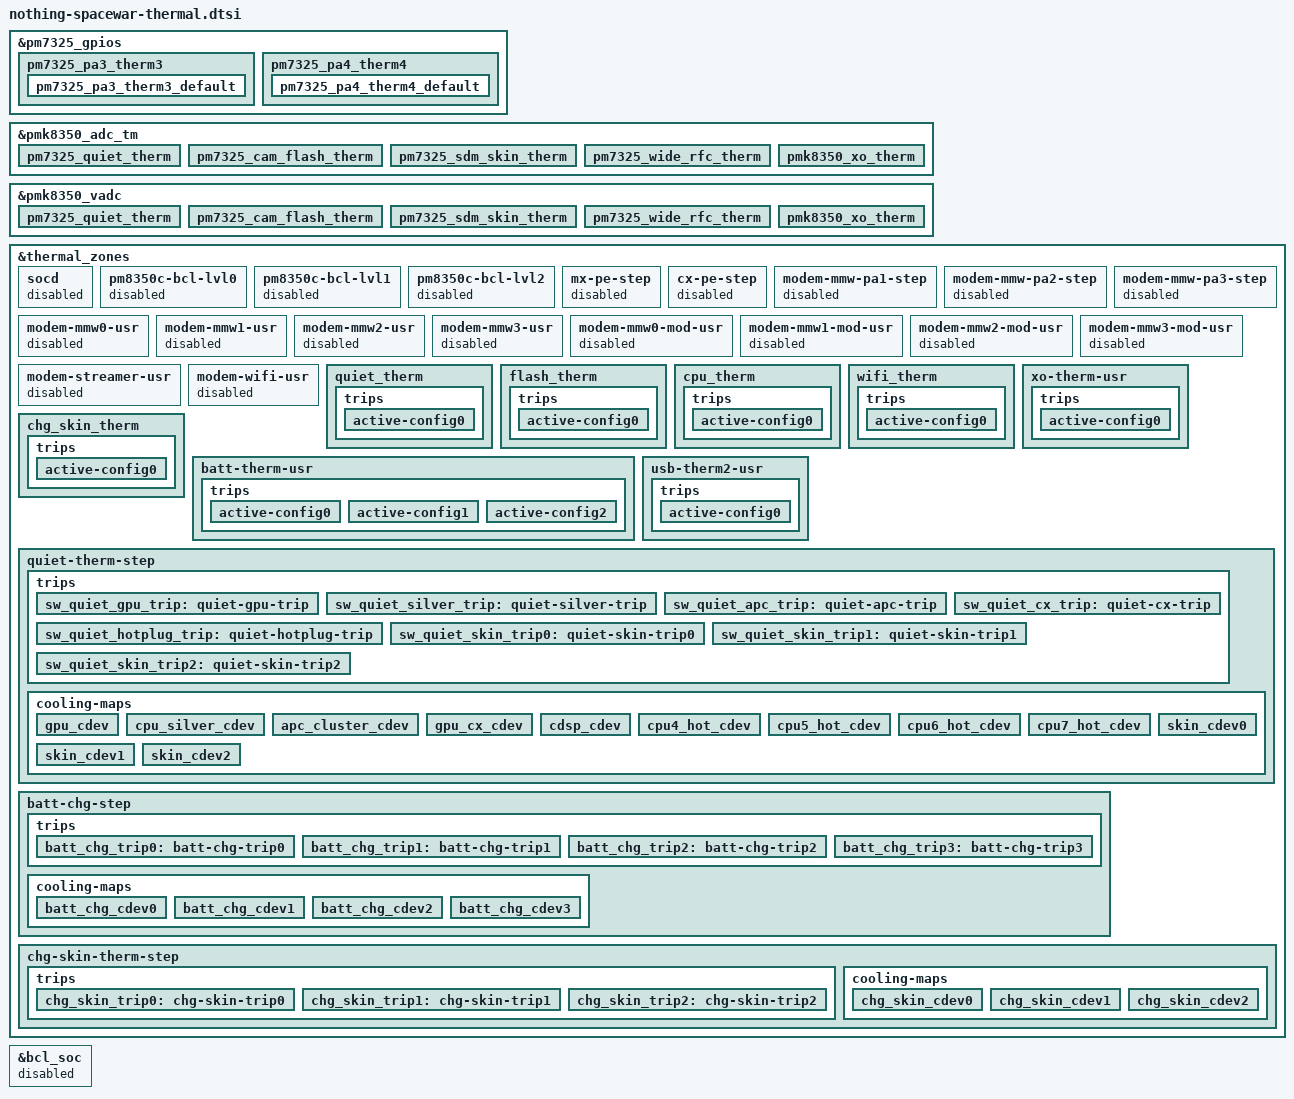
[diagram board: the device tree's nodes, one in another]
#include <dt-bindings/thermal/thermal_qti.h>
#include <dt-bindings/iio/qcom,spmi-adc7-pm7325.h>
#include <dt-bindings/iio/qcom,spmi-adc7-pm8350b.h>
#include <dt-bindings/iio/qcom,spmi-adc7-pmk8350.h>

&pm7325_gpios {
	pm7325_pa3_therm3 {
		pm7325_pa3_therm3_default: pm7325_pa3_therm3_default {
			pins = "gpio2";
			function = "normal";
			bias-high-impedance;
			status = "okay";
		};
	};

	pm7325_pa4_therm4 {
		pm7325_pa4_therm4_default: pm7325_pa4_therm4_default {
			pins = "gpio3";
			function = "normal";
			bias-high-impedance;
			status = "okay";
		};
	};
};

&pmk8350_adc_tm {
	pm7325_quiet_therm {
		reg = <PM7325_ADC7_AMUX_THM1_100K_PU>;
		qcom,ratiometric;
		qcom,hw-settle-time = <200>;
	};

	pm7325_cam_flash_therm {
		reg = <PM7325_ADC7_AMUX_THM2_100K_PU>;
		qcom,ratiometric;
		qcom,hw-settle-time = <200>;
	};

	pm7325_sdm_skin_therm {
		reg = <PM7325_ADC7_AMUX_THM3_100K_PU>;
		qcom,ratiometric;
		qcom,hw-settle-time = <200>;
	};

	pm7325_wide_rfc_therm {
		reg = <PM7325_ADC7_AMUX_THM4_100K_PU>;
		qcom,ratiometric;
		qcom,hw-settle-time = <200>;
	};

	pmk8350_xo_therm {
		reg = <PMK8350_ADC7_AMUX_THM1_100K_PU>;
		qcom,ratiometric;
		qcom,hw-settle-time = <200>;
	};
};

&pmk8350_vadc {
	pm7325_quiet_therm {
		label = "pm7325_quiet_therm";
		reg = <PM7325_ADC7_AMUX_THM1_100K_PU>;
		qcom,ratiometric;
		qcom,hw-settle-time = <200>;
		qcom,pre-scaling = <1 1>;
	};

	pm7325_cam_flash_therm {
		label = "pm7325_cam_flash_therm";
		reg = <PM7325_ADC7_AMUX_THM2_100K_PU>;
		qcom,ratiometric;
		qcom,hw-settle-time = <200>;
		qcom,pre-scaling = <1 1>;
	};

	pm7325_sdm_skin_therm {
		label = "pm7325_sdm_skin_therm";
		reg = <PM7325_ADC7_AMUX_THM3_100K_PU>;
		qcom,ratiometric;
		qcom,hw-settle-time = <200>;
		qcom,pre-scaling = <1 1>;
	};

	pm7325_wide_rfc_therm {
		label = "pm7325_wide_rfc_therm";
		reg = <PM7325_ADC7_AMUX_THM4_100K_PU>;
		qcom,ratiometric;
		qcom,hw-settle-time = <200>;
		qcom,pre-scaling = <1 1>;
	};

	pmk8350_xo_therm {
		label = "pmk8350_xo_therm";
		reg = <PMK8350_ADC7_AMUX_THM1_100K_PU>;
		qcom,ratiometric;
		qcom,hw-settle-time = <200>;
		qcom,pre-scaling = <1 1>;
	};
};

&thermal_zones {
	/delete-node/ pmr735a_tz;

	socd {
		status = "disabled";
		/delete-node/ cooling-maps;
	};

	pm8350c-bcl-lvl0 {
		status = "disabled";
	};

	pm8350c-bcl-lvl1 {
		status = "disabled";
	};

	pm8350c-bcl-lvl2 {
		status = "disabled";
	};

	mx-pe-step {
		status = "disabled";
	};

	cx-pe-step {
		status = "disabled";
	};

	modem-mmw-pa1-step {
		status = "disabled";
	};

	modem-mmw-pa2-step {
		status = "disabled";
	};

	modem-mmw-pa3-step {
		status = "disabled";
	};

	modem-mmw0-usr {
		status = "disabled";
	};

	modem-mmw1-usr {
		status = "disabled";
	};

	modem-mmw2-usr {
		status = "disabled";
	};

	modem-mmw3-usr {
		status = "disabled";
	};

	modem-mmw0-mod-usr {
		status = "disabled";
	};

	modem-mmw1-mod-usr {
		status = "disabled";
	};

	modem-mmw2-mod-usr {
		status = "disabled";
	};

	modem-mmw3-mod-usr {
		status = "disabled";
	};

	modem-streamer-usr {
		status = "disabled";
	};

	modem-wifi-usr {
		status = "disabled";
	};

	quiet_therm {
		polling-delay-passive = <0>;
		polling-delay = <0>;
		thermal-governor = "user_space";
		thermal-sensors = <&pmk8350_adc_tm PM7325_ADC7_AMUX_THM1_100K_PU>;
		wake-capable-sensor;

		trips {
			active-config0 {
				temperature = <125000>;
				hysteresis = <1000>;
				type = "passive";
			};
		};
	};

	flash_therm {
		polling-delay-passive = <0>;
		polling-delay = <0>;
		thermal-governor = "user_space";
		thermal-sensors = <&pmk8350_adc_tm PM7325_ADC7_AMUX_THM2_100K_PU>;
		wake-capable-sensor;

		trips {
			active-config0 {
				temperature = <125000>;
				hysteresis = <1000>;
				type = "passive";
			};
		};
	};

	cpu_therm {
		polling-delay-passive = <0>;
		polling-delay = <0>;
		thermal-governor = "user_space";
		thermal-sensors = <&pmk8350_adc_tm PM7325_ADC7_AMUX_THM3_100K_PU>;
		wake-capable-sensor;

		trips {
			active-config0 {
				temperature = <125000>;
				hysteresis = <1000>;
				type = "passive";
			};
		};
	};

	wifi_therm {
		polling-delay-passive = <0>;
		polling-delay = <0>;
		thermal-governor = "user_space";
		thermal-sensors = <&pmk8350_adc_tm PM7325_ADC7_AMUX_THM4_100K_PU>;
		wake-capable-sensor;

		trips {
			active-config0 {
				temperature = <125000>;
				hysteresis = <1000>;
				type = "passive";
			};
		};
	};

	xo-therm-usr {
		polling-delay-passive = <0>;
		polling-delay = <0>;
		thermal-governor = "user_space";
		thermal-sensors = <&pmk8350_adc_tm PMK8350_ADC7_AMUX_THM1_100K_PU>;
		wake-capable-sensor;

		trips {
			active-config0 {
				temperature = <125000>;
				hysteresis = <1000>;
				type = "passive";
			};
		};
	};

	chg_skin_therm {
		polling-delay-passive = <0>;
		polling-delay = <0>;
		thermal-governor = "user_space";
		thermal-sensors = <&pmk8350_adc_tm_iio_0 PM8350B_ADC7_GPIO2_100K_PU>;
		wake-capable-sensor;

		trips {
			active-config0 {
				temperature = <125000>;
				hysteresis = <1000>;
				type = "passive";
			};
		};
	};

	batt-therm-usr {
		trips {
			active-config0 {
				temperature = <45000>;
				hysteresis = <2000>;
				type = "passive";
			};

			active-config1 {
				temperature = <55000>;
				hysteresis = <2000>;
				type = "passive";
			};

			active-config2 {
				temperature = <60000>;
				hysteresis = <2000>;
				type = "passive";
			};
		};
	};

	usb-therm2-usr {
		trips {
			active-config0 {
				temperature = <125000>;
				hysteresis = <1000>;
				type = "passive";
			};
		};
	};

	quiet-therm-step {
		polling-delay-passive = <2000>;
		polling-delay = <0>;
		thermal-governor = "step_wise";
		thermal-sensors = <&pmk8350_adc_tm PM7325_ADC7_AMUX_THM1_100K_PU>;

		trips {
			sw_quiet_gpu_trip: quiet-gpu-trip {
				temperature = <49000>;
				hysteresis = <2000>;
				type = "passive";
			};

			sw_quiet_silver_trip: quiet-silver-trip {
				temperature = <50000>;
				hysteresis = <2000>;
				type = "passive";
			};

			sw_quiet_apc_trip: quiet-apc-trip {
				temperature = <52000>;
				hysteresis = <2000>;
				type = "passive";
			};

			sw_quiet_cx_trip: quiet-cx-trip {
				temperature = <55000>;
				hysteresis = <3000>;
				type = "passive";
			};

			sw_quiet_hotplug_trip: quiet-hotplug-trip {
				temperature = <60000>;
				hysteresis = <4000>;
				type = "passive";
			};

			sw_quiet_skin_trip0: quiet-skin-trip0 {
				temperature = <50000>;
				hysteresis = <3000>;
				type = "passive";
			};

			sw_quiet_skin_trip1: quiet-skin-trip1 {
				temperature = <54000>;
				hysteresis = <3000>;
				type = "passive";
			};

			sw_quiet_skin_trip2: quiet-skin-trip2 {
				temperature = <58000>;
				hysteresis = <3000>;
				type = "passive";
			};
		};

		cooling-maps {
			gpu_cdev {
				trip = <&sw_quiet_gpu_trip>;
				cooling-device = <&msm_gpu THERMAL_NO_LIMIT
						(THERMAL_MAX_LIMIT-2)>;
			};

			cpu_silver_cdev {
				trip = <&sw_quiet_silver_trip>;
				cooling-device = <&CPU0 THERMAL_NO_LIMIT
						(THERMAL_MAX_LIMIT-4)>;
			};

			apc_cluster_cdev {
				trip = <&sw_quiet_apc_trip>;
				cooling-device = <&apc1_cluster THERMAL_NO_LIMIT 5>;
			};

			gpu_cx_cdev {
				trip = <&sw_quiet_cx_trip>;
				cooling-device = <&msm_gpu THERMAL_MAX_LIMIT
						THERMAL_MAX_LIMIT>;
			};

			cdsp_cdev {
				trip = <&sw_quiet_cx_trip>;
				cooling-device = <&cdsp_sw 4 4>;
			};

			cpu4_hot_cdev {
				trip = <&sw_quiet_hotplug_trip>;
				cooling-device = <&cpu4_hotplug 1 1>;
			};

			cpu5_hot_cdev {
				trip = <&sw_quiet_hotplug_trip>;
				cooling-device = <&cpu5_hotplug 1 1>;
			};

			cpu6_hot_cdev {
				trip = <&sw_quiet_hotplug_trip>;
				cooling-device = <&cpu6_hotplug 1 1>;
			};

			cpu7_hot_cdev {
				trip = <&sw_quiet_hotplug_trip>;
				cooling-device = <&cpu7_hotplug 1 1>;
			};

			skin_cdev0 {
				trip = <&sw_quiet_skin_trip0>;
				cooling-device = <&modem_skin 1 1>;
			};

			skin_cdev1 {
				trip = <&sw_quiet_skin_trip1>;
				cooling-device = <&modem_skin 2 2>;
			};

			skin_cdev2 {
				trip = <&sw_quiet_skin_trip2>;
				cooling-device = <&modem_skin 3 3>;
			};
		};
	};

	batt-chg-step {
		polling-delay-passive = <0>;
		polling-delay = <1000>;
		thermal-governor = "step_wise";
		thermal-sensors = <&pmk8350_adc_tm_iio_0 PM8350B_ADC7_AMUX_THM1_100K_PU>;
		wake-capable-sensor;

		trips {
			batt_chg_trip0: batt-chg-trip0 {
				temperature = <44000>;
				hysteresis = <2000>;
				type = "passive";
			};

			batt_chg_trip1: batt-chg-trip1 {
				temperature = <47000>;
				hysteresis = <2000>;
				type = "passive";
			};

			batt_chg_trip2: batt-chg-trip2 {
				temperature = <50000>;
				hysteresis = <2000>;
				type = "passive";
			};

			batt_chg_trip3: batt-chg-trip3 {
				temperature = <53000>;
				hysteresis = <2000>;
				type = "passive";
			};
		};

		cooling-maps {
			batt_chg_cdev0 {
				trip = <&batt_chg_trip0>;
				cooling-device = <&battery_charger 2 2>;
			};

			batt_chg_cdev1 {
				trip = <&batt_chg_trip1>;
				cooling-device = <&battery_charger 5 5>;
			};

			batt_chg_cdev2 {
				trip = <&batt_chg_trip2>;
				cooling-device = <&battery_charger 9 9>;
			};

			batt_chg_cdev3 {
				trip = <&batt_chg_trip3>;
				cooling-device = <&battery_charger 12 12>;
			};
		};
	};

	chg-skin-therm-step {
		polling-delay-passive = <0>;
		polling-delay = <1000>;
		thermal-governor = "step_wise";
		thermal-sensors = <&pmk8350_adc_tm_iio_0 PM8350B_ADC7_GPIO2_100K_PU>;
		wake-capable-sensor;

		trips {
			chg_skin_trip0: chg-skin-trip0 {
				temperature = <55000>;
				hysteresis = <2000>;
				type = "passive";
			};

			chg_skin_trip1: chg-skin-trip1 {
				temperature = <60000>;
				hysteresis = <2000>;
				type = "passive";
			};

			chg_skin_trip2: chg-skin-trip2 {
				temperature = <65000>;
				hysteresis = <2000>;
				type = "passive";
			};
		};

		cooling-maps {
			chg_skin_cdev0 {
				trip = <&chg_skin_trip0>;
				cooling-device = <&battery_charger 1 1>;
			};

			chg_skin_cdev1 {
				trip = <&chg_skin_trip1>;
				cooling-device = <&battery_charger 4 4>;
			};

			chg_skin_cdev2 {
				trip = <&chg_skin_trip2>;
				cooling-device = <&battery_charger 8 8>;
			};
		};
	};
};

&bcl_soc {
	status = "disabled";
};
